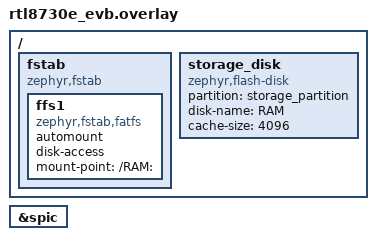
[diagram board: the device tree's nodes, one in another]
/*
 * Copyright (c) 2026 Realtek Semiconductor Corp.
 *
 * SPDX-License-Identifier: Apache-2.0
 *
 * The sample's main.c hard-codes FILE_PATH "/RAM:/hello.txt", so the
 * disk-name is kept as "RAM" and the mount-point as "/RAM:" even though
 * the underlying medium here is the SoC NOR flash partition.  Renaming
 * would require patching the upstream sample source.  fatfs ffconf.h's
 * _VOLUME_STRS already lists "RAM", so no FatFs-side changes are needed.
 */

&spic {
	status = "okay";
};

/ {
	fstab {
		compatible = "zephyr,fstab";
		ffs1: ffs1 {
			compatible = "zephyr,fstab,fatfs";
			automount;
			disk-access;
			mount-point = "/RAM:";
		};
	};

	storage_disk {
		compatible = "zephyr,flash-disk";
		partition = <&storage_partition>;
		disk-name = "RAM";
		cache-size = <4096>;
	};
};
